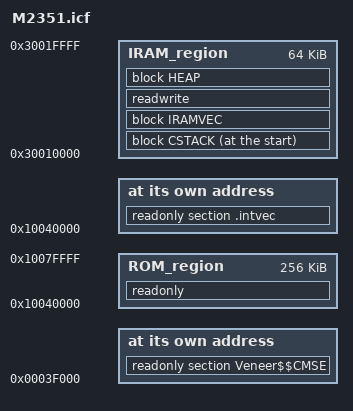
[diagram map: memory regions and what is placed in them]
/*###ICF### Section handled by ICF editor, don't touch! ****/
/*-Editor annotation file-*/
/* IcfEditorFile="$TOOLKIT_DIR$\config\ide\IcfEditor\cortex_v1_0.xml" */

if (isdefinedsymbol(__DOMAIN_NS)) {
/*-Specials-*/
define symbol __ICFEDIT_intvec_start__ = 0x10040000;
/*-Memory Regions-*/
define symbol __ICFEDIT_region_ROM_start__ = 0x10040000;
define symbol __ICFEDIT_region_ROM_end__   = 0x10080000 - 1;
define symbol __ICFEDIT_region_IRAM_start__ = 0x30010000;
define symbol __ICFEDIT_region_IRAM_end__   = 0x30020000 - 1;
} else {
/*-Specials-*/
define symbol __ICFEDIT_intvec_start__ = 0x00000000;
/*-Memory Regions-*/
define symbol __ICFEDIT_region_ROM_start__ = 0x00000000;
define symbol __ICFEDIT_region_ROM_end__   = 0x0003F000 - 1;
define symbol __ICFEDIT_region_NSCROM_start__ = 0x0003F000;
define symbol __ICFEDIT_region_NSCROM_end__   = 0x00040000 - 1;
define symbol __ICFEDIT_region_IRAM_start__ = 0x20000000;
define symbol __ICFEDIT_region_IRAM_end__   = 0x20010000 - 1;
}
/*-Sizes-*/
define symbol __ICFEDIT_size_cstack__ = 0x800;
define symbol __ICFEDIT_size_heap__   = 0x4000;
/**** End of ICF editor section. ###ICF###*/


define memory mem with size = 4G;
define region ROM_region   = mem:[from __ICFEDIT_region_ROM_start__   to __ICFEDIT_region_ROM_end__];
define region IRAM_region  = mem:[from __ICFEDIT_region_IRAM_start__  to __ICFEDIT_region_IRAM_end__];

define block CSTACK    with alignment = 8, size = __ICFEDIT_size_cstack__   { };
define block HEAP      with alignment = 8, size = __ICFEDIT_size_heap__     { };
/* NOTE: Vector table base requires to be aligned to the power of vector table size. Give a safe value here. */
define block IRAMVEC   with alignment = 1024, size = 4 * (16 + 102)          { };


initialize by copy { readwrite };
do not initialize  { section .noinit };

place at address mem:__ICFEDIT_intvec_start__ { readonly section .intvec };

place in ROM_region   { readonly };
if (!isdefinedsymbol(__DOMAIN_NS)) {
place at address mem:__ICFEDIT_region_NSCROM_start__ { readonly section Veneer$$CMSE };
}
place at start of IRAM_region   { block CSTACK };
place in IRAM_region   { block IRAMVEC };
place in IRAM_region   { readwrite };
place in IRAM_region   { block HEAP };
